AUTOSAR XML (schema 4-0-3)
standard types defined: Boolean, UInt32
package /AUTOSAR_Platform/DataConstrs
  range DC_Boolean: raw 0..1
package /PATAC/MSM/ComponentTypes
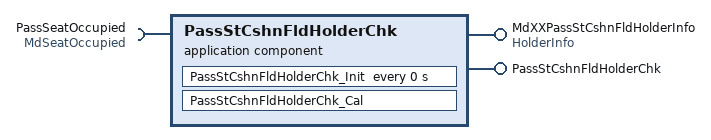
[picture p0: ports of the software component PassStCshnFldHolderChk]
  application sw component type PassStCshnFldHolderChk
    provide port MdXXPassStCshnFldHolderInfo: nonqueued-sender-com-spec{data-element=HolderInfo/Val, init-value=0}, provided-interface=HolderInfo
    provide port PassStCshnFldHolderChk: server-com-spec{operation=Cal, queue-length=1}, provided-interface=PassStCshnFldHolderChk
    require port PassSeatOccupied: nonqueued-receiver-com-spec{data-element=MdSeatOccupied/Val, filter=data-filter-type=ALWAYS, init-value=0}, required-interface=MdSeatOccupied
    behavior PassStCshnFldHolderChk_InternalBehavior
      operation invoked event OIT_PassStCshnFldHolderChk_Cal_PassStCshnFldHolderChk_Cal: start-on-event=PassStCshnFldHolderChk_Cal, operation=PassStCshnFldHolderChk.Cal
      timing event PassStCshnFldHolderChk_InitEvent: start-on-event=PassStCshnFldHolderChk_Init, period=0
      runnable PassStCshnFldHolderChk_Cal
        data-receive-point-by-arguments:
          access REC_PassSeatOccupied_Val: accessed-variable=PassSeatOccupied.Val
        data-send-points:
          access SEND_MdXXPassStCshnFldHolderInfo_Val: accessed-variable=MdXXPassStCshnFldHolderInfo.Val
      runnable PassStCshnFldHolderChk_Init
  swc implementation PassStCshnFldHolderChk_Implementation: behavior=PassStCshnFldHolderChk_InternalBehavior
    code-descriptors:
      code Default: artifact-descriptors=autosar-engineering-object={short-label=Default, category=SWSRC}
package /PATAC/MSM/ModeAdjust/PortInterface
  client server interface PassStCshnFldHolderChk
    operation Cal
  sender receiver interface HolderInfo: invalidation-policy{data-element=HolderInfo/Val, handle-invalid=DONT-INVALIDATE}
    data Val: type=UInt32
  sender receiver interface MdSeatOccupied: invalidation-policy{data-element=MdSeatOccupied/Val, handle-invalid=DONT-INVALIDATE}
    data Val: type=Boolean
